VERSION "xc90-2008my-lowspeed-2"

NS_ :

BS_:

BU_: XC90

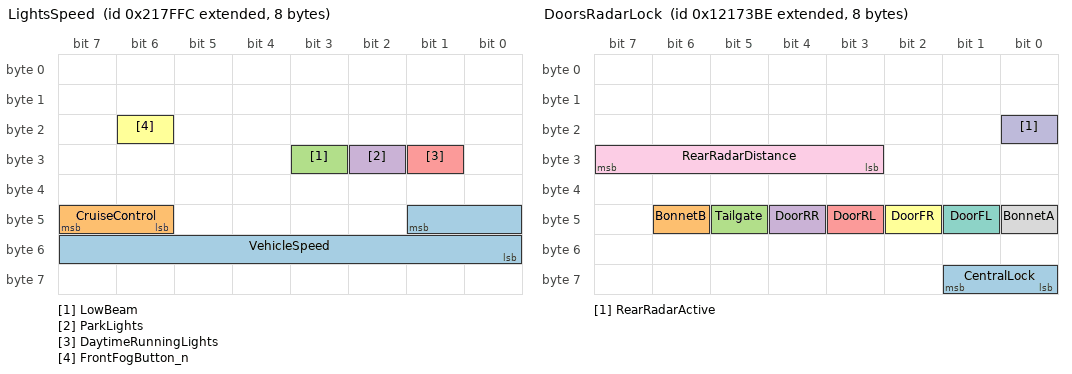
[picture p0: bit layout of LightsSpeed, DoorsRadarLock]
BO_ 2149679100 LightsSpeed: 8 Vector__XXX
 SG_ VehicleSpeed : 41|10@0+ (0.25,0) [0|0] "km/h"  XC90
 SG_ CruiseControl : 46|2@1+ (1,0) [0|0] ""  XC90
 SG_ LowBeam : 27|1@1+ (1,0) [0|0] ""  XC90
 SG_ ParkLights : 26|1@1+ (1,0) [0|0] ""  XC90
 SG_ DaytimeRunningLights : 25|1@1+ (1,0) [0|0] ""  XC90
 SG_ FrontFogButton_n : 22|1@1+ (1,0) [0|0] ""  XC90

BO_ 2158035976 TurnLamps: 8 Vector__XXX
 SG_ TurnLampRight : 58|1@1+ (1,0) [0|0] ""  XC90
 SG_ TurnLampLeft : 57|1@1+ (1,0) [0|0] ""  XC90

BO_ 2167501420 SteeringWheelModule: 8 Vector__XXX
 SG_ TripReset : 63|1@1+ (1,0) [0|0] ""  XC90
 SG_ KeyPickup : 61|1@1+ (1,0) [0|0] ""  XC90
 SG_ KeyHangup : 60|1@1+ (1,0) [0|0] ""  XC90
 SG_ KeyVolumeUp_n : 59|1@1+ (1,0) [0|0] ""  XC90
 SG_ KeyVolumeDown_n : 58|1@1+ (1,0) [0|0] ""  XC90
 SG_ KeyNext : 57|1@1+ (1,0) [0|0] ""  XC90
 SG_ KeyPrev : 56|1@1+ (1,0) [0|0] ""  XC90
 SG_ TurnStalkLeft : 55|1@1+ (1,0) [0|0] ""  XC90
 SG_ TurnStalkRight : 54|1@1+ (1,0) [0|0] ""  XC90
 SG_ NavEnter : 53|1@1+ (1,0) [0|0] ""  XC90
 SG_ NavBack : 52|1@1+ (1,0) [0|0] ""  XC90
 SG_ NavUp : 51|1@1+ (1,0) [0|0] ""  XC90
 SG_ NavDown : 50|1@1+ (1,0) [0|0] ""  XC90
 SG_ NavLeft : 49|1@1+ (1,0) [0|0] ""  XC90
 SG_ NavRight : 48|1@1+ (1,0) [0|0] ""  XC90
 SG_ WiperSingle : 47|1@1+ (1,0) [0|0] ""  XC90
 SG_ TripWheel : 40|3@1+ (1,0) [0|0] ""  XC90
 SG_ WiperInterval : 37|3@1+ (1,0) [0|0] ""  XC90
 SG_ WiperUnknown : 36|1@1+ (1,0) [0|0] ""  XC90
 SG_ WiperIntermittent : 35|1@1+ (1,0) [0|0] ""  XC90
 SG_ WiperMedium : 34|1@1+ (1,0) [0|0] ""  XC90
 SG_ WiperHigh : 33|1@1+ (1,0) [0|0] ""  XC90
 SG_ RearWiperSwitch : 12|1@1+ (1,0) [0|0] ""  XC90
 SG_ ClimateDemand : 0|6@1+ (1,0) [0|0] ""  XC90

BO_ 2166453182 DoorsRadarLock: 8 Vector__XXX
 SG_ CentralLock : 56|2@1+ (1,0) [0|0] ""  XC90
 SG_ BonnetB : 46|1@1+ (1,0) [0|0] ""  XC90
 SG_ Tailgate : 45|1@1+ (1,0) [0|0] ""  XC90
 SG_ DoorRR : 44|1@1+ (1,0) [0|0] ""  XC90
 SG_ DoorRL : 43|1@1+ (1,0) [0|0] ""  XC90
 SG_ DoorFR : 42|1@1+ (1,0) [0|0] ""  XC90
 SG_ DoorFL : 41|1@1+ (1,0) [0|0] ""  XC90
 SG_ BonnetA : 40|1@1+ (1,0) [0|0] ""  XC90
 SG_ RearRadarDistance : 27|5@1+ (1,0) [0|0] ""  XC90
 SG_ RearRadarActive : 16|1@1+ (1,0) [0|0] ""  XC90

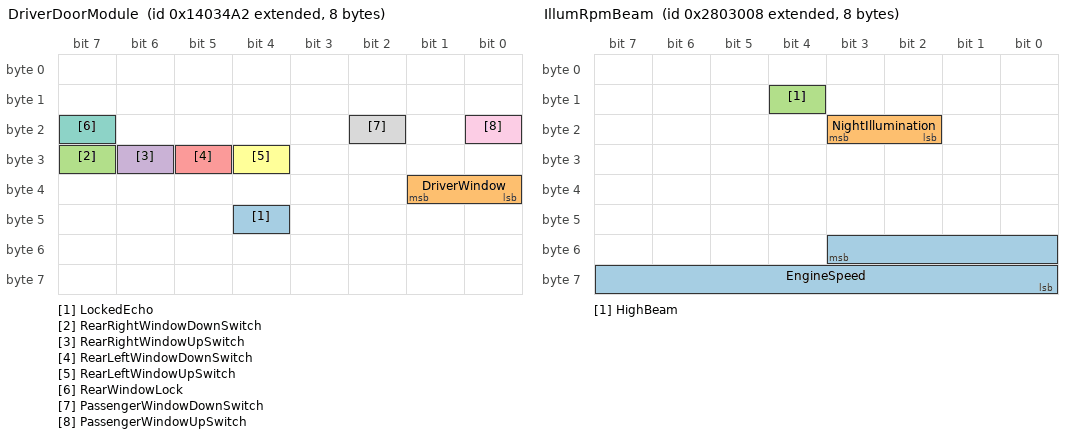
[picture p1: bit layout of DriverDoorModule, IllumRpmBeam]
BO_ 2168468642 DriverDoorModule: 8 Vector__XXX
 SG_ LockedEcho : 44|1@1+ (1,0) [0|0] ""  XC90
 SG_ DriverWindow : 32|2@1+ (1,0) [0|0] ""  XC90
 SG_ RearRightWindowDownSwitch : 31|1@1+ (1,0) [0|0] ""  XC90
 SG_ RearRightWindowUpSwitch : 30|1@1+ (1,0) [0|0] ""  XC90
 SG_ RearLeftWindowDownSwitch : 29|1@1+ (1,0) [0|0] ""  XC90
 SG_ RearLeftWindowUpSwitch : 28|1@1+ (1,0) [0|0] ""  XC90
 SG_ RearWindowLock : 23|1@1+ (1,0) [0|0] ""  XC90
 SG_ PassengerWindowDownSwitch : 18|1@1+ (1,0) [0|0] ""  XC90
 SG_ PassengerWindowUpSwitch : 16|1@1+ (1,0) [0|0] ""  XC90

BO_ 2178946602 Sunroof: 8 Vector__XXX
 SG_ WiperSingleEcho : 53|1@1+ (1,0) [0|0] ""  XC90
 SG_ SunroofState : 16|8@1+ (1,0) [0|0] ""  XC90

BO_ 2186346528 SteeringAngle: 8 Vector__XXX
 SG_ SteeringAngleMagnitude : 48|6@1+ (1,0) [0|0] ""  XC90
 SG_ SteeringDirection : 42|1@1+ (1,0) [0|0] ""  XC90

BO_ 2187422972 RearFog: 8 Vector__XXX
 SG_ RearFogB : 31|1@1+ (1,0) [0|0] ""  XC90
 SG_ RearFogA : 21|1@1+ (1,0) [0|0] ""  XC90

BO_ 2189438984 IllumRpmBeam: 8 Vector__XXX
 SG_ EngineSpeed : 51|12@0+ (1,0) [0|0] "rpm"  XC90
 SG_ NightIllumination : 18|2@1+ (1,0) [0|0] ""  XC90
 SG_ HighBeam : 12|1@1+ (1,0) [0|0] ""  XC90

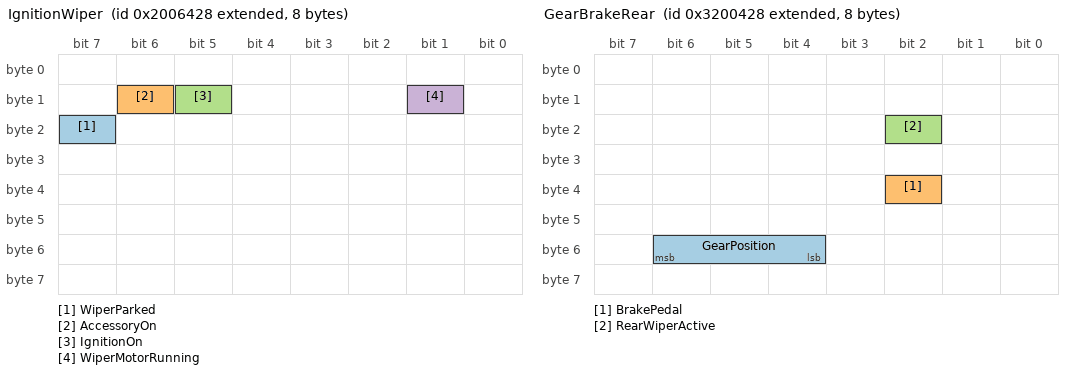
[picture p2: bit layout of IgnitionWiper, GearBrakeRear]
BO_ 2181063720 IgnitionWiper: 8 Vector__XXX
 SG_ WiperParked : 23|1@1+ (1,0) [0|0] ""  XC90
 SG_ AccessoryOn : 14|1@1+ (1,0) [0|0] ""  XC90
 SG_ IgnitionOn : 13|1@1+ (1,0) [0|0] ""  XC90
 SG_ WiperMotorRunning : 9|1@1+ (1,0) [0|0] ""  XC90

BO_ 2199913512 GearBrakeRear: 8 Vector__XXX
 SG_ GearPosition : 52|3@1+ (1,0) [0|0] ""  XC90
 SG_ BrakePedal : 34|1@1+ (1,0) [0|0] ""  XC90
 SG_ RearWiperActive : 18|1@1+ (1,0) [0|0] ""  XC90

BO_ 2214592514 Odometer: 8 Vector__XXX
 SG_ OdometerKm : 47|24@0+ (1,0) [0|0] "km"  XC90

BO_ 2206290540 FuelLevel: 8 Vector__XXX
 SG_ FuelLevelPercent : 48|8@1+ (1,0) [0|0] "%"  XC90

BO_ 2183144034 DriverBelt: 8 Vector__XXX
 SG_ DriverBeltBuckled : 35|1@1+ (1,0) [0|0] ""  XC90
 SG_ ParkingBrakeEcho : 31|1@1+ (1,0) [0|0] ""  XC90

BO_ 2208317444 ParkingBrake: 8 Vector__XXX
 SG_ ParkingBrakeApplied : 8|1@1+ (1,0) [0|0] ""  XC90

BO_ 2210403368 OutsideTemp: 8 Vector__XXX
 SG_ OutsideTempRaw : 48|8@1+ (1,0) [0|0] ""  XC90

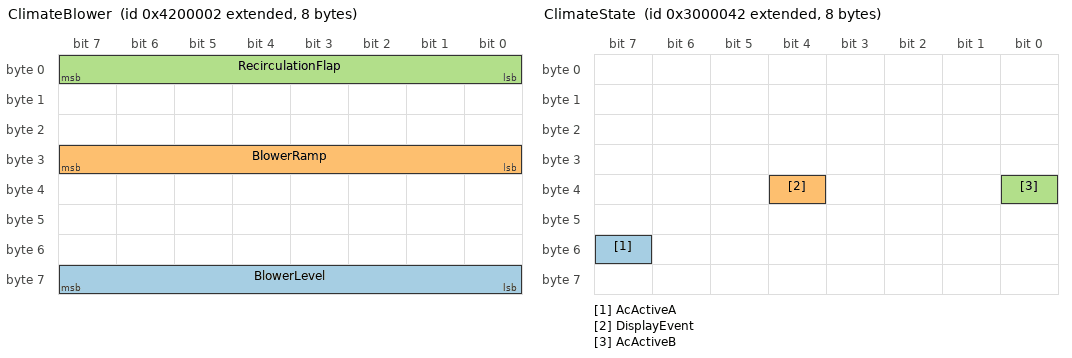
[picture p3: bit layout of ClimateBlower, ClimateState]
BO_ 2216689666 ClimateBlower: 8 Vector__XXX
 SG_ BlowerLevel : 56|8@1+ (1,0) [0|0] ""  XC90
 SG_ BlowerRamp : 24|8@1+ (1,0) [0|0] ""  XC90
 SG_ RecirculationFlap : 0|8@1+ (1,0) [0|0] "%"  XC90

BO_ 2162167816 ClimateAc: 8 Vector__XXX
 SG_ AcOff : 3|2@1+ (1,0) [0|0] ""  XC90

BO_ 2160067586 ClimateHeaters: 8 Vector__XXX
 SG_ RearWindowHeater : 55|1@1+ (1,0) [0|0] ""  XC90

BO_ 2197815362 ClimateState: 8 Vector__XXX
 SG_ AcActiveA : 55|1@1+ (1,0) [0|0] ""  XC90
 SG_ DisplayEvent : 36|1@1+ (1,0) [0|0] ""  XC90
 SG_ AcActiveB : 32|1@1+ (1,0) [0|0] ""  XC90

CM_ "Volvo XC90 MY2008 (P2), low-speed CAN: 125 kbit/s, 29-bit ids, OBD pins 3/11. Decoded by passive sniffing (GVRET listen-only) and from canbox-xc90-my2008 cars/xc90_2008my.c; signals marked Confirmed were checked step by step on 2026-10-15. NOT on this bus: the temperature setpoints (both sides), seat heat, an AUTO flag, front fog state, and the passenger and rear window states.";
CM_ BO_ 2149679100 "Light switch module and vehicle speed (firmware lsm0 + vel handlers).";
CM_ SG_ 2149679100 VehicleSpeed "Low 10 bits of bytes 5-6, /4. Firmware: confirmed working.";
CM_ SG_ 2149679100 CruiseControl "Cruise control main switch. Confirmed 2026-10-16. The +, -, resume buttons are not on this bus.";
CM_ SG_ 2149679100 LowBeam "The parking bit clears when low beam is selected.";
CM_ SG_ 2149679100 DaytimeRunningLights "Set with the light switch at off (F2); cleared at parking (F4) and low beam (F8). Confirmed 2026-10-15.";
CM_ SG_ 2149679100 FrontFogButton_n "Drops to 0 for about 1 s when the front fog button is pressed (also seen once during a climate step, so treat with care). The front fog STATE is not on this bus.";
CM_ BO_ 2158035976 "Turn indicator lamps, toggling with the flash (about 1.5 Hz). Only sent while indicators run; hazards set both bits (0x0E). Confirmed 2026-10-15/16.";
CM_ BO_ 2167501420 "Steering wheel module: keys (firmware swm handler), turn and wiper stalks.";
CM_ SG_ 2167501420 TripReset "Trip computer reset button (end of the left stalk). Confirmed 2026-10-16.";
CM_ SG_ 2167501420 KeyPickup "Pickup and hangup are swapped compared with MY2007.";
CM_ SG_ 2167501420 KeyVolumeUp_n "Active low.";
CM_ SG_ 2167501420 KeyVolumeDown_n "Active low.";
CM_ SG_ 2167501420 TurnStalkLeft "Confirmed 2026-10-15.";
CM_ SG_ 2167501420 TurnStalkRight "Confirmed 2026-10-15.";
CM_ SG_ 2167501420 NavRight "Left and right are swapped compared with MY2007.";
CM_ SG_ 2167501420 WiperSingle "Stalk pushed up for a single wipe. Confirmed 2026-10-15.";
CM_ SG_ 2167501420 TripWheel "Trip computer thumbwheel on the left stalk. Changes on every notch (seen 0, 3, 5, 7, then 4 turning back); encoding unclear, probably a rotary code.";
CM_ SG_ 2167501420 WiperInterval "Interval ring position 0-7 (faster wipes with higher values: about 19, 12, 8 s at standstill). Confirmed 2026-10-15.";
CM_ SG_ 2167501420 WiperUnknown "Set for 0.5 s once after the stalk went to off. Possibly the washer; unconfirmed.";
CM_ SG_ 2167501420 WiperIntermittent "Front wiper stalk: off, intermittent, medium, high (bits 3, 2, 1). All clear = off. Confirmed 2026-10-15.";
CM_ SG_ 2167501420 RearWiperSwitch "Rear wiper switch on. Confirmed 2026-10-15.";
CM_ SG_ 2167501420 ClimateDemand "Byte 0 bits 0-5. Jumps with temperature setpoint changes and decays; 0 with AC off; 0x1F briefly after a climate button. Climate controller demand, NOT the displayed setpoint. Bit 7 toggles every frame.";
CM_ BO_ 2166453182 "Rear electronic module: doors, rear park assist (firmware rem handler) and central locking.";
CM_ SG_ 2166453182 CentralLock "Central locking state (inside button and key fob, confirmed 2026-10-15/16). 3 appears 26 s after locking with the fob, probably the alarm arming; unconfirmed. After a fob lock most modules stop sending within 3 s and the bus is silent about 1 minute later; the fob unlock wakes it, first frame 0x1B500000.";
CM_ SG_ 2166453182 BonnetA "Firmware treats bit 0 or bit 6 as bonnet open.";
CM_ SG_ 2166453182 RearRadarDistance "Nearest obstacle, one value for all rear sensors. The firmware scales 0..31 to 0..99.";
CM_ BO_ 2168468642 "Driver door module: window switches, rear-window lock, driver window state.";
CM_ SG_ 2168468642 LockedEcho "Set while locked (follows CentralLock).";
CM_ SG_ 2168468642 DriverWindow "Confirmed 2026-10-15. No such state was seen for the other windows.";
CM_ SG_ 2168468642 RearWindowLock "Rear-window lock button state, 1 = rear windows locked. Confirmed 2026-10-15.";
CM_ SG_ 2178946602 WiperSingleEcho "Follows WiperSingle.";
CM_ SG_ 2178946602 SunroofState "00 closed, 01 briefly while moving, 02 open (tilted vs slid not yet separated). Confirmed 2026-10-15.";
CM_ BO_ 2186346528 "Steering angle, sign-magnitude, coarse. The firmware notes the direction is reversed.";
CM_ SG_ 2187422972 RearFogA "Rear fog light on. Confirmed 2026-10-15 (one of the two bits is probably the switch, the other the lamp).";
CM_ BO_ 2189438984 "Illumination (firmware lsm1), main beam and engine rpm.";
CM_ SG_ 2189438984 EngineSpeed "Low 12 bits of bytes 6-7. Firmware: confirmed working.";
CM_ SG_ 2189438984 HighBeam "Main beam, including a flash. Confirmed 2026-10-15.";
CM_ BO_ 2181063720 "Key position (firmware acc handler) and front wiper motor.";
CM_ SG_ 2181063720 WiperParked "0 for about 1 s during each front wipe. Confirmed 2026-10-15.";
CM_ SG_ 2181063720 IgnitionOn "Byte 1: 0xE3 running (bit 7 toggles), 0x43 key at accessory, 0x03 key out. Seen at switch-off 2026-10-16; the bus stayed awake after key out.";
CM_ SG_ 2181063720 WiperMotorRunning "Set briefly at the start and end of each wipe.";
CM_ BO_ 2199913512 "Gear selector (firmware gear handler), brake pedal, rear wiper output.";
CM_ SG_ 2199913512 BrakePedal "Brake pedal pressed. Confirmed 2026-10-15.";
CM_ SG_ 2199913512 RearWiperActive "On while the rear wiper runs. Confirmed 2026-10-15.";
CM_ BO_ 2214592514 "Firmware: confirmed working.";
CM_ BO_ 2206290540 "Byte 5 increments slowly (counter).";
CM_ SG_ 2206290540 FuelLevelPercent "Firmware: likely correct; tank 80 l on the V8.";
CM_ SG_ 2183144034 DriverBeltBuckled "Firmware: confirmed working.";
CM_ SG_ 2183144034 ParkingBrakeEcho "Follows ParkingBrakeApplied.";
CM_ SG_ 2208317444 ParkingBrakeApplied "1 = applied: released and reapplied with the pedal on 2026-10-15. The firmware sends ~bit (park_break = ~msg[1] & 1) and calls it confirmed; check which sense the head unit expects.";
CM_ SG_ 2210403368 OutsideTempRaw "Scaling not worked out (firmware TODO); read 0 on 2026-10-15.";
CM_ BO_ 2216689666 "Climate blower and recirculation. Confirmed 2026-10-15.";
CM_ SG_ 2216689666 BlowerLevel "Fan step. Ramps through about one intermediate value per 0.7 s between steps. AUTO and defrost choose their own value (defrost: 0x86).";
CM_ SG_ 2216689666 BlowerRamp "Follows BlowerLevel with a larger scale and wraps past 0xFF. Use BlowerLevel.";
CM_ SG_ 2216689666 RecirculationFlap "100 (0x64) in manual recirculation, 0 in off and auto.";
CM_ BO_ 2162167816 "Bytes 3 and 5 move with blower load. The firmware's commented-out ccm handler guessed recirculation was in byte 1 here; it is in 0x4200002 byte 0.";
CM_ SG_ 2162167816 AcOff "0x03 with AC on, 0x1B with AC off (also when the fan is at 0). Confirmed 2026-10-15.";
CM_ BO_ 2160067586 "Byte 3 tracks the climate demand like 0x131726C byte 0. Byte 7 is analog.";
CM_ SG_ 2160067586 RearWindowHeater "Confirmed 2026-10-15.";
CM_ BO_ 2197815362 "Bytes 3 and 7 are analog climate values (air mix, probably evaporator or outlet temperature).";
CM_ SG_ 2197815362 AcActiveA "Clears with AC off.";
CM_ SG_ 2197815362 DisplayEvent "Drops for about 0.1 s on trip computer READ and thumbwheel use, and on some climate changes. Meaning unclear.";
CM_ SG_ 2197815362 AcActiveB "Clears with AC off.";

VAL_ 2149679100 CruiseControl 1 "Off" 2 "On" ;
VAL_ 2166453182 CentralLock 1 "Locked" 2 "Unlocked" 3 "LockedArmed" ;
VAL_ 2168468642 DriverWindow 1 "Closed" 2 "Open" ;
VAL_ 2178946602 SunroofState 0 "Closed" 1 "Moving" 2 "Open" ;
VAL_ 2186346528 SteeringDirection 0 "Negative" 1 "Positive" ;
VAL_ 2199913512 GearPosition 1 "P" 2 "R" 3 "N" 4 "D" ;
VAL_ 2208317444 ParkingBrakeApplied 0 "Released" 1 "Applied" ;
VAL_ 2216689666 BlowerLevel 0 "Off" 17 "Step1" 32 "Step2" 47 "Step3" 64 "Step4" 84 "Step5" 108 "Step6" 134 "Step7" ;
VAL_ 2162167816 AcOff 0 "On" 3 "Off" ;
